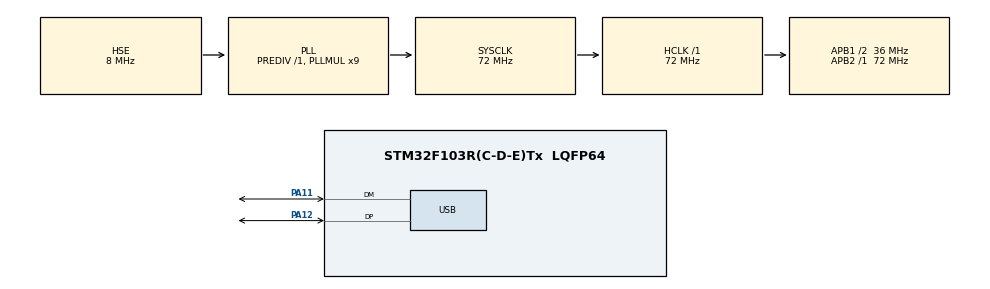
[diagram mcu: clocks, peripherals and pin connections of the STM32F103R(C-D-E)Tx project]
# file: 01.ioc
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Mcu.Family=STM32F1
Mcu.Name=STM32F103R(C-D-E)Tx
Mcu.Package=LQFP64
NVIC.PriorityGroup=NVIC_PRIORITYGROUP_4
NVIC.USB_LP_CAN1_RX0_IRQn=true\:0\:0\:false\:false\:true\:false
PA11.Mode=Device
PA11.Signal=USB_DM
PA12.Mode=Device
PA12.Signal=USB_DP
PD0-OSC_IN.Mode=HSE-External-Oscillator
PD0-OSC_IN.Signal=RCC_OSC_IN
PD1-OSC_OUT.Mode=HSE-External-Oscillator
PD1-OSC_OUT.Signal=RCC_OSC_OUT
ProjectManager.HeapSize=0x200
ProjectManager.StackSize=0x400
ProjectManager.TargetToolchain=MDK-ARM V5
RCC.AHBFreq_Value=72000000
RCC.APB1CLKDivider=RCC_HCLK_DIV2
RCC.APB1Freq_Value=36000000
RCC.APB1TimFreq_Value=72000000
RCC.APB2Freq_Value=72000000
RCC.APB2TimFreq_Value=72000000
RCC.HCLKFreq_Value=72000000
RCC.PLLMUL=RCC_PLL_MUL9
RCC.SYSCLKFreq_VALUE=72000000
RCC.SYSCLKSource=RCC_SYSCLKSOURCE_PLLCLK
RCC.USBFreq_Value=48000000
RCC.USBPrescaler=RCC_USBCLKSOURCE_PLL_DIV1_5
USB.ep0_mps=DEP0CTL_MPS_64
USB_DEVICE.CLASS_NAME_FS=CUSTOMHID
USB_DEVICE.PRODUCT_STRING_CUSTOMHID_FS=NPL Lab
USB_DEVICE.USBD_CUSTOMHID_OUTREPORT_BUF_SIZE=64
USB_DEVICE.USBD_CUSTOM_HID_REPORT_DESC_SIZE=32
USB_DEVICE.VirtualMode=CustomHid
USB_DEVICE.VirtualModeFS=Custom_Hid_FS
VP_SYS_VS_ND.Mode=No_Debug
VP_USB_DEVICE_VS_USB_DEVICE_CUSTOM_HID_FS.Mode=CUSTOM_HID_FS
board=01

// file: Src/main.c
#include "main.h"
#include "stm32f1xx_hal.h"
#include "usb_device.h"
#include "usbd_customhid.h"
#include "bsp_led.h"

void SystemClock_Config(void);
static void MX_GPIO_Init(void);

uint8_t flg_wake_up  = 0 ;

uint8_t keys[8] = {0};

uint32_t delay_cnt = 0 ;

int main(void)
{

  /* USER CODE BEGIN 1 */
	// HID Keyboard
  struct keyboardHID_t {
      uint8_t id;
      uint8_t modifiers;
      uint8_t key1;
      uint8_t key2;
      uint8_t key3;
  };
  struct keyboardHID_t keyboardHID;
  keyboardHID.id = 1;
  keyboardHID.modifiers = 0;
  keyboardHID.key1 = 0;
  keyboardHID.key2 = 0;
  keyboardHID.key3 = 0;
  // HID Media
  struct mediaHID_t {
    uint8_t id;
    uint8_t keys;
  };
//  struct mediaHID_t mediaHID;
//  mediaHID.id = 2;
//  mediaHID.keys = 0;

  /* USER CODE END 1 */

  /* MCU Configuration----------------------------------------------------------*/

  /* Reset of all peripherals, Initializes the Flash interface and the Systick. */
  HAL_Init();

  /* Configure the system clock */
  SystemClock_Config();

  /* Initialize all configured peripherals */
  MX_GPIO_Init();
  MX_USB_DEVICE_Init();

  /* Infinite loop */
  while (1)
  {

  /* USER CODE BEGIN 3 */
	  if(flg_wake_up)
	  {
		    wakeup :
			flg_wake_up = 0 ;

			keyboardHID.modifiers = 0;
			keyboardHID.key1 = 0;
			USBD_CUSTOM_HID_SendReport(&hUsbDeviceFS, (uint8_t*)&keyboardHID, sizeof(struct keyboardHID_t));
			HAL_Delay(20);

			keyboardHID.modifiers = 0;//USB_HID_MODIFIER_RIGHT_SHIFT
			keyboardHID.key1 = 0x45;//USB_HID_KEY_L+('K'-'L')//0x45
			USBD_CUSTOM_HID_SendReport(&hUsbDeviceFS, (uint8_t*)&keyboardHID, sizeof(struct keyboardHID_t));

			delay_cnt = 500 ;
			while(--delay_cnt)
			{
				HAL_Delay(10);
				if(flg_wake_up)
				{
					goto wakeup ;
				}
			}

			keyboardHID.modifiers = 0;
			keyboardHID.key1 = 0;
			USBD_CUSTOM_HID_SendReport(&hUsbDeviceFS, (uint8_t*)&keyboardHID, sizeof(struct keyboardHID_t));
			HAL_Delay(20);

			flg_wake_up = 0 ;

	  }
  }
  /* USER CODE END 3 */

}

/** System Clock Configuration
*/
void SystemClock_Config(void)
{

  RCC_OscInitTypeDef RCC_OscInitStruct;
  RCC_ClkInitTypeDef RCC_ClkInitStruct;
  RCC_PeriphCLKInitTypeDef PeriphClkInit;

    /**Initializes the CPU, AHB and APB busses clocks
    */
  RCC_OscInitStruct.OscillatorType = RCC_OSCILLATORTYPE_HSE;
  RCC_OscInitStruct.HSEState = RCC_HSE_ON;
  RCC_OscInitStruct.HSEPredivValue = RCC_HSE_PREDIV_DIV1;
  RCC_OscInitStruct.HSIState = RCC_HSI_ON;
  RCC_OscInitStruct.PLL.PLLState = RCC_PLL_ON;
  RCC_OscInitStruct.PLL.PLLSource = RCC_PLLSOURCE_HSE;
  RCC_OscInitStruct.PLL.PLLMUL = RCC_PLL_MUL9;
  if (HAL_RCC_OscConfig(&RCC_OscInitStruct) != HAL_OK)
  {
    _Error_Handler(__FILE__, __LINE__);
  }

    /**Initializes the CPU, AHB and APB busses clocks
    */
  RCC_ClkInitStruct.ClockType = RCC_CLOCKTYPE_HCLK|RCC_CLOCKTYPE_SYSCLK
                              |RCC_CLOCKTYPE_PCLK1|RCC_CLOCKTYPE_PCLK2;
  RCC_ClkInitStruct.SYSCLKSource = RCC_SYSCLKSOURCE_PLLCLK;
  RCC_ClkInitStruct.AHBCLKDivider = RCC_SYSCLK_DIV1;
  RCC_ClkInitStruct.APB1CLKDivider = RCC_HCLK_DIV2;
  RCC_ClkInitStruct.APB2CLKDivider = RCC_HCLK_DIV1;

  if (HAL_RCC_ClockConfig(&RCC_ClkInitStruct, FLASH_LATENCY_2) != HAL_OK)
  {
    _Error_Handler(__FILE__, __LINE__);
  }

  PeriphClkInit.PeriphClockSelection = RCC_PERIPHCLK_USB;
  PeriphClkInit.UsbClockSelection = RCC_USBCLKSOURCE_PLL_DIV1_5;
  if (HAL_RCCEx_PeriphCLKConfig(&PeriphClkInit) != HAL_OK)
  {
    _Error_Handler(__FILE__, __LINE__);
  }

    /**Configure the Systick interrupt time
    */
  HAL_SYSTICK_Config(HAL_RCC_GetHCLKFreq()/1000);

    /**Configure the Systick
    */
  HAL_SYSTICK_CLKSourceConfig(SYSTICK_CLKSOURCE_HCLK);

  /* SysTick_IRQn interrupt configuration */
  HAL_NVIC_SetPriority(SysTick_IRQn, 0, 0);
}

/** Configure pins as
        * Analog
        * Input
        * Output
        * EVENT_OUT
        * EXTI
*/
static void MX_GPIO_Init(void)
{
	GPIO_InitTypeDef GPIO_InitStruct;

	/* GPIO Ports Clock Enable */
	__HAL_RCC_GPIOD_CLK_ENABLE();
	__HAL_RCC_GPIOA_CLK_ENABLE();
	__HAL_RCC_GPIOC_CLK_ENABLE();

  /*Configure GPIO pin : PC7 */
  GPIO_InitStruct.Pin = GPIO_PIN_7;
  GPIO_InitStruct.Mode = GPIO_MODE_IT_RISING;
  GPIO_InitStruct.Pull = GPIO_NOPULL;
  HAL_GPIO_Init(GPIOC, &GPIO_InitStruct);

  /* EXTI interrupt init*/
  HAL_NVIC_SetPriority(EXTI9_5_IRQn, 1, 0);
  HAL_NVIC_EnableIRQ(EXTI9_5_IRQn);

//	/*Configure GPIO pin : PA15 */
//	GPIO_InitStruct.Pin = GPIO_PIN_15;
//	GPIO_InitStruct.Mode = GPIO_MODE_IT_RISING;
//	GPIO_InitStruct.Pull = GPIO_NOPULL;
//	HAL_GPIO_Init(GPIOA, &GPIO_InitStruct);

//	/* EXTI interrupt init*/
//	HAL_NVIC_SetPriority(EXTI15_10_IRQn, 1, 0);
//	HAL_NVIC_EnableIRQ(EXTI15_10_IRQn);

}

void _Error_Handler(char * file, int line)
{
  while(1)
  {
  }
}

/************************ (C) COPYRIGHT STMicroelectronics *****END OF FILE****/
